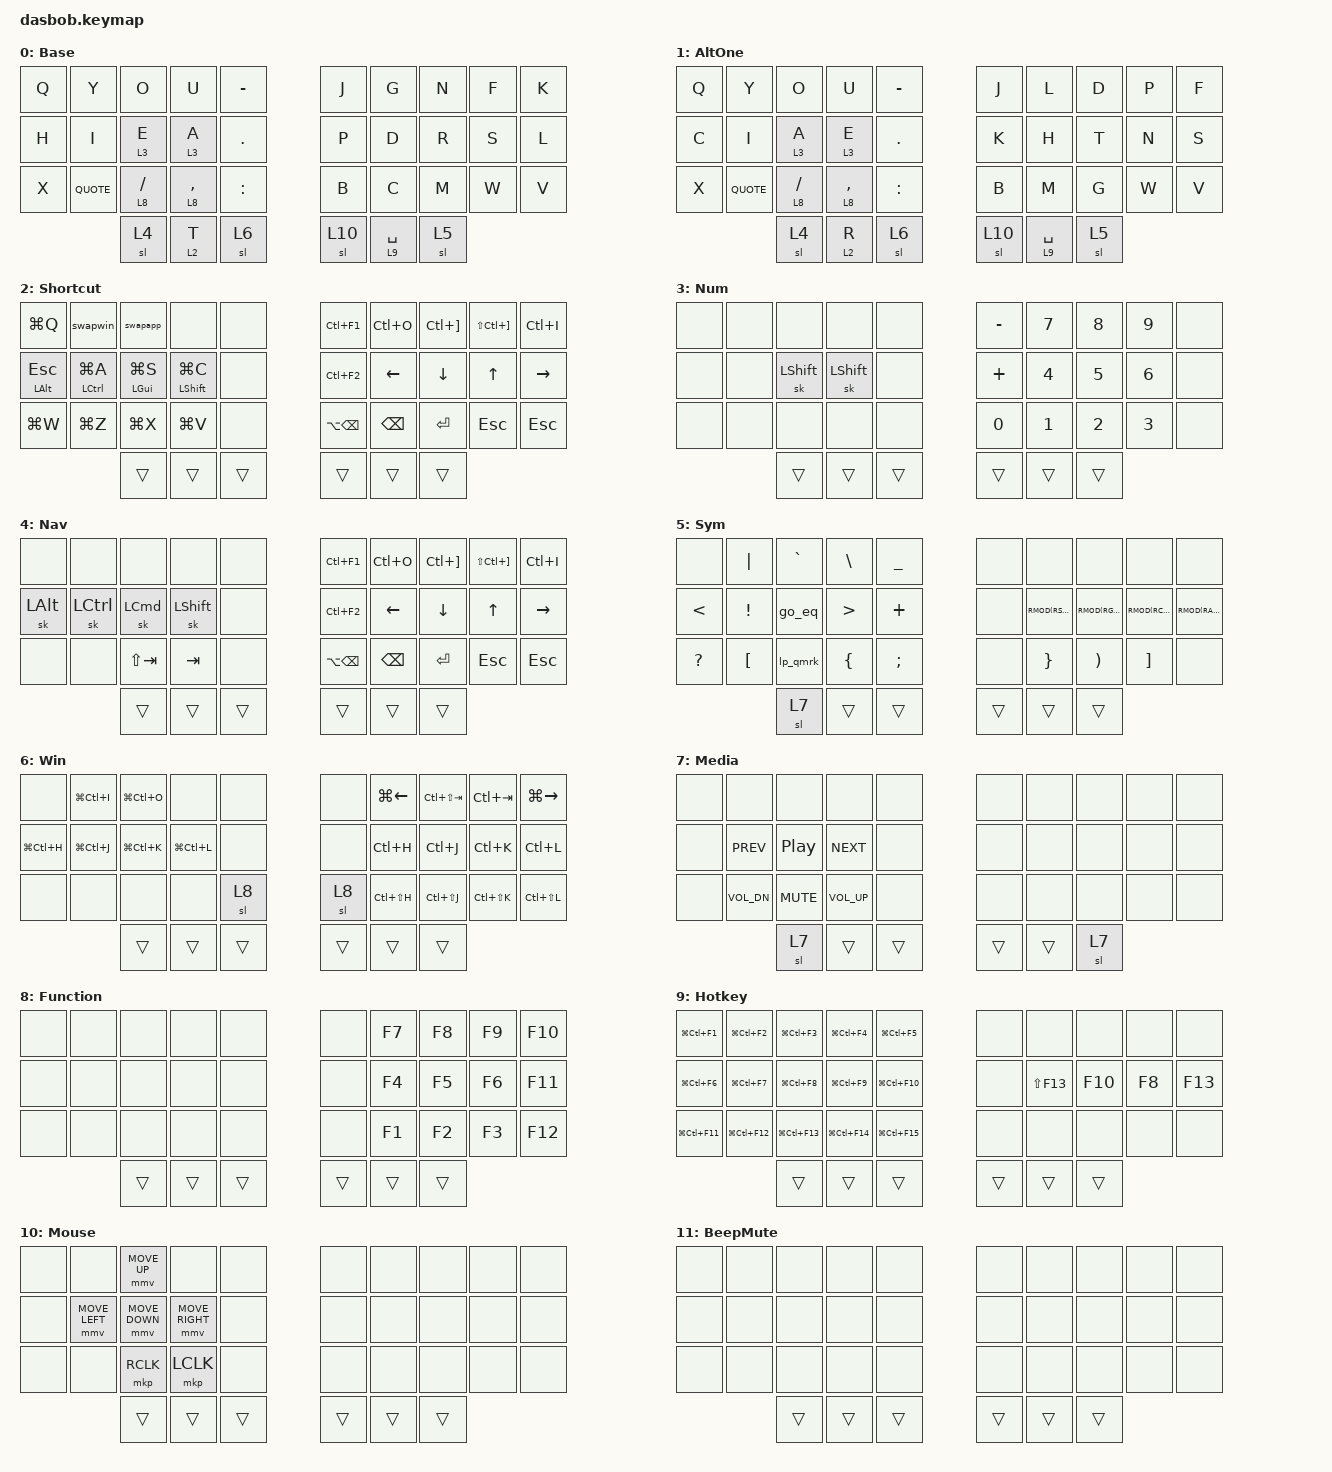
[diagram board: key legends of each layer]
#include <behaviors.dtsi>
#include <dt-bindings/zmk/keys.h>
#include <dt-bindings/zmk/pointing.h>
#include <dt-bindings/zmk/bt.h>
#include <zephyr/dt-bindings/pwm/pwm.h>

#define OUTPUT_SOURCE_LAYER_STATE_CHANGE 1
#define AS(keycode)      &as LS(keycode) keycode  // Autoshift preprocessor macro

#define LCMD_T(keycode)  &lt 3 keycode              // Mod-tap preprocessor macro for Command (GUI)
#define LALT_T(keycode)  &kp keycode              // Hold-tap preprocessor macro for Alt
#define LSFT_T(keycode)  &lt 3 keycode              // Hold-tap preprocessor macro for Shift
#define LCTL_T(keycode)  &kp keycode              // Hold-tap preprocessor macro for Control

#define RCMD_T(keycode)  &kp keycode              // Hold-tap preprocessor macro for Right Command (Right GUI)
#define RALT_T(keycode)  &kp keycode              // Hold-tap preprocessor macro for Right Alt
#define RSFT_T(keycode)  &kp keycode              // Hold-tap preprocessor macro for Right Shift
#define RCTL_T(keycode)  &kp keycode              // Hold-tap preprocessor macro for Right Control

#define SPC_T(keycode)   &spc_t SPACE keycode     // Hold Space, tap keycode


#define LMOD(keycode) &sk keycode
#define RMOD(keycode) &sk keycode

#define QUOTE SINGLE_QUOTE

&mt {
    tapping-term-ms = <400>;
};

&sk {
    release-after-ms = <1000>;
    quick-release;
};

&caps_word {
    continue-list = <UNDERSCORE MINUS>;
    mods = <(MOD_LSFT)>;
};

&key_repeat {
    usage-pages = <HID_USAGE_KEY HID_USAGE_CONSUMER>;
};

/ {
    piezo: piezo {
        compatible = "zmk,output-pwm";
        #binding-cells = <0>;
        pwms = <&pwm0 0 PWM_HZ(4100) PWM_POLARITY_NORMAL>;
    };

    piezo_tick: piezo_tick {
        compatible = "zmk,output-behavior-generic";
        #binding-cells = <0>;
        device = <&piezo>;
        delay = <10>;
        force = <128>;
        time-to-live-ms = <25>;
    };

    piezo_tick_delayed: piezo_tick_delayed {
        compatible = "zmk,output-behavior-generic";
        #binding-cells = <0>;
        device = <&piezo>;
        delay = <70>;
        force = <128>;
        time-to-live-ms = <25>;
    };

    base_layer_beep {
        compatible = "zmk,output-behavior-listener";
        layers = <0>;
        sources = <OUTPUT_SOURCE_LAYER_STATE_CHANGE>;
        position = <1>;
        invert-state;
        bindings = <&piezo_tick>;
    };

    alt_one_layer_beep {
        compatible = "zmk,output-behavior-listener";
        layers = <1>;
        sources = <OUTPUT_SOURCE_LAYER_STATE_CHANGE>;
        position = <1>;
        bindings = <&piezo_tick &piezo_tick_delayed>;
    };

    base_layer_beep_guard {
        compatible = "zmk,output-behavior-listener";
        layers = <0>;
        sources = <OUTPUT_SOURCE_LAYER_STATE_CHANGE>;
        position = <1>;
        invert-state;
        bindings = <&beep_guard>;
    };

    alt_one_layer_beep_guard {
        compatible = "zmk,output-behavior-listener";
        layers = <1>;
        sources = <OUTPUT_SOURCE_LAYER_STATE_CHANGE>;
        position = <1>;
        bindings = <&beep_guard>;
    };

    behaviors {
        hml: home_row_mod_left {
            compatible = "zmk,behavior-hold-tap";
            #binding-cells = <2>;
            flavor = "balanced";
            require-prior-idle-ms = <150>;
            tapping-term-ms = <280>;
            quick-tap-ms = <175>;
            bindings = <&kp>, <&kp>;
            hold-trigger-key-positions = < 0 1 2 3 4 10 11 12 13 14 20 21 22 23 24 30 31 32 >;
            hold-trigger-on-release;
        };

        hmr: home_row_mod_right {
            compatible = "zmk,behavior-hold-tap";
            #binding-cells = <2>;
            flavor = "balanced";
            require-prior-idle-ms = <150>;
            tapping-term-ms = <280>;
            quick-tap-ms = <175>;
            bindings = <&kp>, <&kp>;
            hold-trigger-key-positions = < 5 6 7 8 9 15 16 17 18 19 25 26 27 28 29 33 34 35 >;
            hold-trigger-on-release;
        };

        spc_t: space_hold_tap {
            compatible = "zmk,behavior-hold-tap";
            #binding-cells = <2>;
            flavor = "tap-preferred";
            tapping-term-ms = <200>;
            quick-tap-ms = <175>;
            bindings = <&kp>, <&kp>;
        };

        as_hold: auto_shift_hold {
            compatible = "zmk,behavior-macro-one-param";
            #binding-cells = <1>;
            bindings
                = <&macro_press &kp LSHFT>
                , <&macro_param_1to1>
                , <&macro_tap &kp MACRO_PLACEHOLDER>
                , <&macro_release &kp LSHFT>
                ;
        };

        as: auto_shift {
            compatible = "zmk,behavior-hold-tap";
            label = "AUTO_SHIFT";
            bindings = <&as_hold>, <&kp>;
            #binding-cells = <2>;
            tapping_term_ms = <200>;
            quick_tap_ms = <0>;
            flavor = "tap-preferred";
        };

        sml: sticky_mod_layer {
            compatible = "zmk,behavior-sticky-mod-layer";
            #binding-cells = <2>;
            release-after-ms = <750>;
            quick-release;
            ignore-modifiers;
            ignored-key-positions = <30 32 33 35>;
            bindings = <&kp>;
        };

        kt_on: key_toggle_on {
            compatible = "zmk,behavior-key-toggle";
            #binding-cells = <1>;
            toggle-mode = "on";
        };

        kt_off: key_toggle_off {
            compatible = "zmk,behavior-key-toggle";
            #binding-cells = <1>;
            toggle-mode = "off";
        };

        swapapp: swapapp {
            compatible = "zmk,behavior-tri-state";
            #binding-cells = <0>;
            // Use explicit on/off semantics so sticky GUI state cannot invert the swapper.
            bindings = <&kt_on LGUI>, <&kp TAB>, <&kt_off LGUI>;
            ignored-key-positions = <0 2 16 17 18 19>;
        };

        swapwin: swapwin {
            compatible = "zmk,behavior-tri-state";
            #binding-cells = <0>;
            bindings = <&kt_on LGUI>, <&kp GRAVE>, <&kt_off LGUI>;
            ignored-key-positions = <1>;
        };

        magic_key: magic_key {
            compatible = "zmk,behavior-magic-key";
            #binding-cells = <0>;
            label = "MAGIC_KEY";
        };

        go_dec: go_dec {
            compatible = "zmk,behavior-macro";
            #binding-cells = <0>;
            bindings = <&kp COLON &kp EQUAL>;
        };

        go_eq: go_eq {
            compatible = "zmk,behavior-mod-morph";
            #binding-cells = <0>;
            bindings = <&kp EQUAL>, <&go_dec>;
            mods = <(MOD_LSFT|MOD_RSFT)>;
        };

        lp_qmrk: lp_qmrk {
            compatible = "zmk,behavior-mod-morph";
            #binding-cells = <0>;
            bindings = <&kp LPAR>, <&kp QMARK>;
            mods = <(MOD_LSFT|MOD_RSFT)>;
        };

        beep_guard: beep_guard {
            compatible = "zmk,behavior-macro";
            #binding-cells = <0>;
            bindings = <&macro_press &macro_wait_time 120 &mo 11
                        &macro_release &macro_wait_time 0 &mo 11>;
        };

    };

    combos {
        compatible = "zmk,combos";

        alt_one_combo {
            timeout-ms = <50>; // Max delay between keys.
            key-positions = <32 33>;
            bindings = <&tog 1>;
        };

        bootloader_combo {
            timeout-ms = <50>; // Max delay between keys.
            key-positions = <4 5>;
            bindings = <&bootloader>;
        };

        reset_combo {
            timeout-ms = <50>; // Max delay between keys.
            key-positions = <0 9>;
            bindings = <&sys_reset>;
        };

        capsword_combo {
            timeout-ms = <50>; // Max delay between keys.
            key-positions = <14 15>;
            bindings = <&caps_word>;
        };

        capslock_combo {
            timeout-ms = <50>; // Max delay between keys.
            key-positions = <24 25>;
            bindings = <&kp CAPSLOCK>;
        };

        enter_combo {
            timeout-ms = <30>; // Max delay between keys.
            key-positions = <27 28>;
            bindings = <&kp ENTER>;
        };
    };

    keymap {
        compatible = "zmk,keymap";

        Base { // 0
            bindings = <
                &kp Q             &kp Y             &kp O             &kp U             &kp MINUS         /**/  &kp J             &kp G             &kp N           &kp F             &kp K
                &kp H             &kp I             &lt 3 E           &lt 3 A           &kp DOT           /**/  &kp P             &kp D             &kp R           &kp S             &kp L
                &kp X             &kp QUOTE         &lt 8 SLASH       &lt 8 COMMA       &kp COLON         /**/  &kp B             &kp C             &kp M           &kp W             &kp V
                                                    &sl 4             &lt 2 T           &sl 6             /**/  &sl 10            &lt 9  SPACE      &sl 5
            >;
        };

        AltOne { // 1
            bindings = <
                &kp Q             &kp Y             &kp O             &kp U             &kp MINUS       /**/  &kp J             &kp L           &kp D           &kp P             &kp F
                &kp C             &kp I             &lt 3 A           &lt 3 E           &kp DOT         /**/  &kp K             &kp H           &kp T           &kp N             &kp S
                &kp X             &kp QUOTE         &lt 8 SLASH       &lt 8 COMMA       &kp COLON       /**/  &kp B             &kp M           &kp G           &kp W             &kp V
                                                    &sl 4             &lt 2 R           &sl 6           /**/  &sl 10            &lt 9  SPACE    &sl 5
            >;
        };

        Shortcut { // 2
            bindings = <
                &kp LG(Q)         &swapwin          &swapapp          &none             &none             /**/  &kp LC(F1)        &kp LC(O)         &kp LC(RBKT)      &kp LS(LC(RBKT))  &kp LC(I)
                &mt LALT ESC      &mt LCTL LG(A)    &mt LGUI LG(S)    &mt LSHFT LG(C)   &none             /**/  &kp LC(F2)        &kp LEFT          &kp DOWN          &kp UP            &kp RIGHT
                &kp LG(W)         &kp LG(Z)         &kp LG(X)         &kp LG(V)         &none             /**/  &kp LA(BSPC)      &kp BSPC          &kp ENTER         &kp ESC           &kp ESC
                                                    &trans            &trans            &trans            /**/  &trans            &trans            &trans
            >;
        };

        Num { // 3
            bindings = <
                &none             &none             &none             &none             &none             /**/  &kp MINUS         &kp N7            &kp N8            &kp N9            &none
                &none             &none             &sk LSHFT         &sk LSHFT         &none             /**/  &kp PLUS          &kp N4            &kp N5            &kp N6            &none
                &none             &none             &none             &none             &none             /**/  &kp N0            &kp N1            &kp N2            &kp N3            &none
                                                    &trans            &trans            &trans            /**/  &trans            &trans            &trans
            >;
        };

        Nav { // 4
            bindings = <
                &none             &none             &none             &none             &none             /**/  &kp LC(F1)        &kp LC(O)         &kp LC(RBKT)      &kp LS(LC(RBKT))  &kp LC(I)
                &sk LALT          &sk LCTRL         &sk LCMD          &sk LSHFT         &none             /**/  &kp LC(F2)        &kp LEFT          &kp DOWN          &kp UP            &kp RIGHT
                &none             &none             &kp LS(TAB)       &kp TAB           &none             /**/  &kp LA(BSPC)      &kp BSPC          &kp ENTER         &kp ESC           &kp ESC
                                                    &trans            &trans            &trans            /**/  &trans            &trans            &trans
            >;
        };

        Sym { // 5
            bindings = <
                &none          &kp PIPE          &kp GRAVE         &kp BSLH          &kp UNDER         /**/  &none             &none             &none             &none             &none
                &kp LT         &kp EXCL          &go_eq            &kp GT            &kp PLUS          /**/  &none             RMOD(RSHFT)       RMOD(RGUI)        RMOD(RCTRL)       RMOD(RALT)
                &kp QMARK      &kp LBKT          &lp_qmrk          &kp LBRC          &kp SEMI          /**/  &none             &kp RBRC          &kp RPAR          &kp RBKT          &none
                                                 &sl 7             &trans            &trans            /**/  &trans            &trans            &trans
            >;
        };

        Win { // 6
            bindings = <
                &none             &kp LG(LC(I))     &kp LG(LC(O))     &none             &none             /**/  &none             &kp LG(LEFT)      &kp LC(LS(TAB))   &kp LC(TAB)       &kp LG(RIGHT)
                &kp LG(LC(H))     &kp LG(LC(J))     &kp LG(LC(K))     &kp LG(LC(L))     &none             /**/  &none             &kp LC(H)         &kp LC(J)         &kp LC(K)         &kp LC(L)
                &none             &none             &none             &none             &sl 8             /**/  &sl 8             &kp LC(LS(H))     &kp LC(LS(J))     &kp LC(LS(K))     &kp LC(LS(L))
                                                    &trans            &trans            &trans            /**/  &trans            &trans            &trans
            >;
        };

        Media { // 7
            bindings = <
                &none             &none             &none             &none             &none             /**/  &none             &none             &none             &none             &none
                &none             &kp C_PREV        &kp C_PLAY_PAUSE  &kp C_NEXT        &none             /**/  &none             &none             &none             &none             &none
                &none             &kp C_VOL_DN      &kp C_MUTE        &kp C_VOL_UP      &none             /**/  &none             &none             &none             &none             &none
                                                    &sl 7             &trans            &trans            /**/  &trans            &trans            &sl 7
            >;
        };

        Function { // 8
            bindings = <
                &none             &none             &none             &none             &none             /**/  &none             &kp F7            &kp F8            &kp F9            &kp F10
                &none             &none             &none             &none             &none             /**/  &none             &kp F4            &kp F5            &kp F6            &kp F11
                &none             &none             &none             &none             &none             /**/  &none             &kp F1            &kp F2            &kp F3            &kp F12
                                                    &trans            &trans            &trans            /**/  &trans            &trans            &trans
            >;
        };

        Hotkey { // 9
            bindings = <
                &kp LG(LC(F1))        &kp LG(LC(F2))        &kp LG(LC(F3))        &kp LG(LC(F4))        &kp LG(LC(F5))        /**/  &none        &none             &none             &none             &none
                &kp LG(LC(F6))        &kp LG(LC(F7))        &kp LG(LC(F8))        &kp LG(LC(F9))        &kp LG(LC(F10))       /**/  &none        &kp LS(F13)       &kp F10           &kp F8            &kp F13
                &kp LG(LC(F11))       &kp LG(LC(F12))       &kp LG(LC(F13))       &kp LG(LC(F14))       &kp LG(LC(F15))       /**/  &none        &none             &none             &none             &none
                                                            &trans                &trans                &trans                /**/  &trans       &trans            &trans
            >;
        };

        Mouse { // 10
            bindings = <
                &none     &none             &mmv MOVE_UP      &none             &none             /**/  &none             &none             &none          &none             &none
                &none     &mmv MOVE_LEFT    &mmv MOVE_DOWN    &mmv MOVE_RIGHT   &none             /**/  &none             &none             &none          &none             &none
                &none     &none             &mkp RCLK         &mkp LCLK         &none             /**/  &none             &none             &none          &none             &none
                                            &trans            &trans            &trans            /**/  &trans            &trans            &trans
            >;
        };

        BeepMute { // 11
            bindings = <
                &none             &none             &none             &none             &none             /**/  &none             &none             &none             &none             &none
                &none             &none             &none             &none             &none             /**/  &none             &none             &none             &none             &none
                &none             &none             &none             &none             &none             /**/  &none             &none             &none             &none             &none
                                                    &trans            &trans            &trans            /**/  &trans            &trans            &trans
            >;
        };
    };
};
